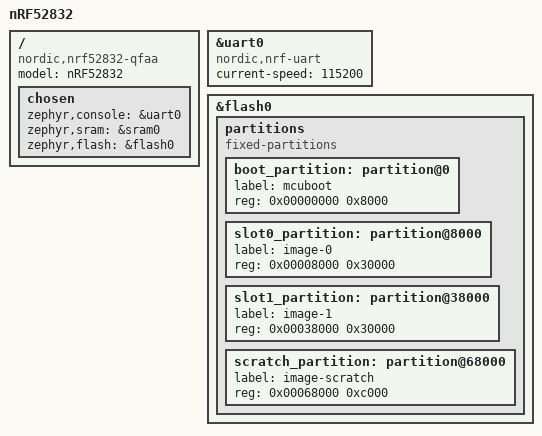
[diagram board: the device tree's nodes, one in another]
/*
 * Copyright (c) 2017 Linaro Limited
 *
 * SPDX-License-Identifier: Apache-2.0
 */

/dts-v1/;
#include <nordic/nrf52832.dtsi>

/ {
	model = "nRF52832";
	compatible = "nordic,nrf52832-qfaa",
		     "nordic,nrf52832";

	chosen {
		zephyr,console = &uart0;
		zephyr,sram = &sram0;
		zephyr,flash = &flash0;
	};
};

&uart0 {
	compatible = "nordic,nrf-uart";
	current-speed = <115200>;
	status = "ok";
};

&flash0 {
	/*
	 * If chosen's zephyr,code-partition
	 * is unset, the image will be linked
	 * into the entire flash device.  If
	 * it points to an individual
	 * partition, the code will be linked
	 * to, and restricted to that
	 * partition.
	 */
	partitions {
		compatible = "fixed-partitions";
		#address-cells = <1>;
		#size-cells = <1>;

		boot_partition: partition@0 {
			label = "mcuboot";
			reg = <0x00000000 0x8000>;
		};
		/* The size of this partition must be
		 * devidible by the size of the scratch partition
		 * and 4k aligned.
		 */
		slot0_partition: partition@8000 {
			label = "image-0";
			reg = <0x00008000 0x30000>;
		};
		// Same size like slot0_partition
		slot1_partition: partition@38000 {
			label = "image-1";
			reg = <0x00038000 0x30000>;
		};
		scratch_partition: partition@68000 {
			label = "image-scratch";
			reg = <0x00068000 0xc000>;
		};

		/*
		 * The flash starting at 0x00074000 and ending at
		 * 0x0007ffff is reserved for use by the application.
		 */
	};
};
